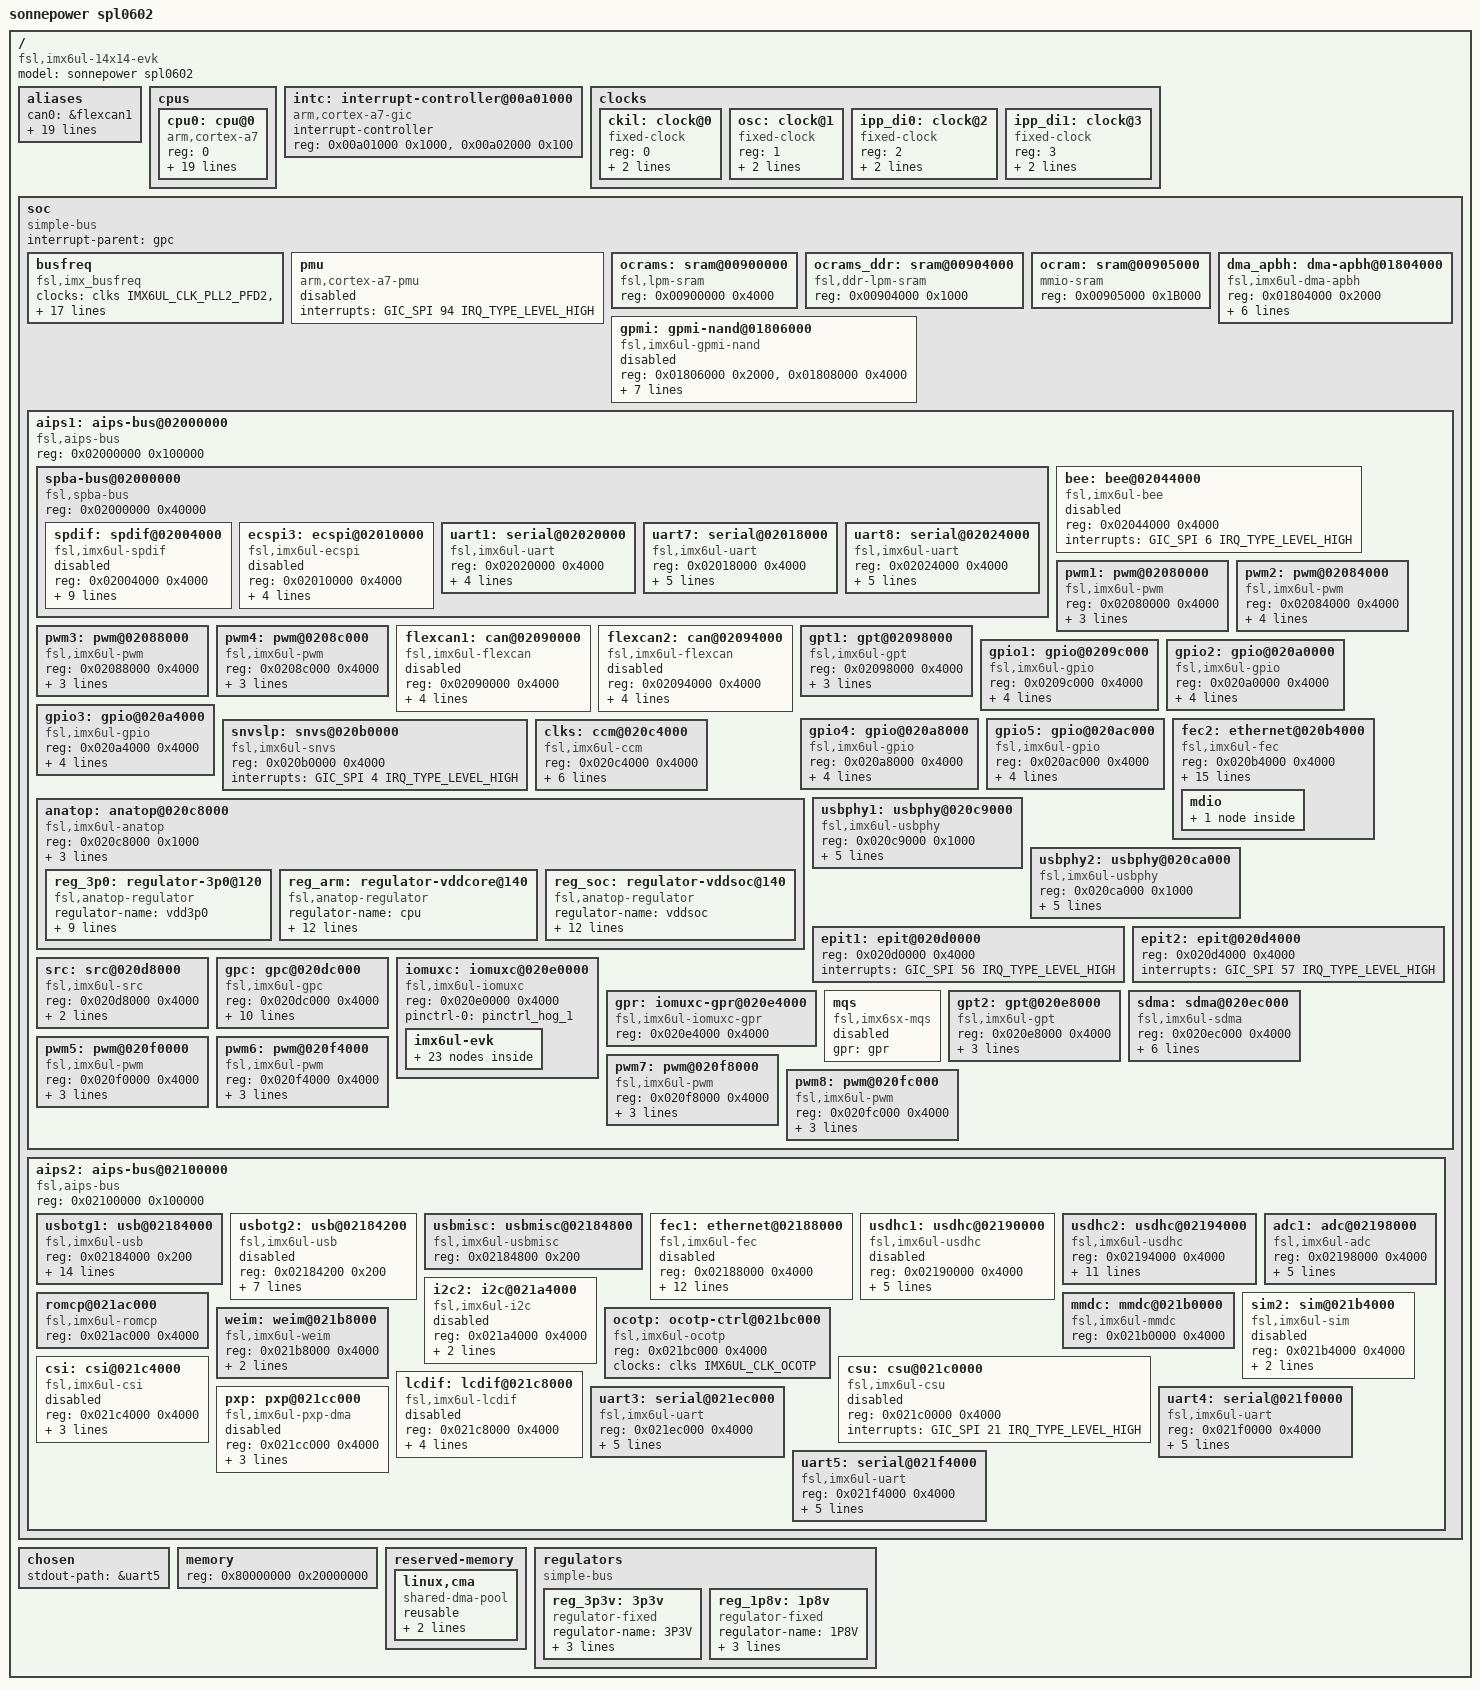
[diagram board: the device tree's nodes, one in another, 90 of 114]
/*
 * Copyright (C) 2016 Freescale Semiconductor, Inc.
 *
 * This program is free software; you can redistribute it and/or modify
 * it under the terms of the GNU General Public License version 2 as
 * published by the Free Software Foundation.
 */

/dts-v1/;

#include <dt-bindings/clock/imx6ul-clock.h>
#include <dt-bindings/gpio/gpio.h>
#include <dt-bindings/interrupt-controller/arm-gic.h>
#include "imx6ul-pinfunc.h"
#include "skeleton.dtsi"

/ {
	aliases {
		can0 = &flexcan1;
		can1 = &flexcan2;
		ethernet0 = &fec2;
		gpio0 = &gpio1;
		gpio1 = &gpio2;
		gpio2 = &gpio3;
		gpio3 = &gpio4;
		gpio4 = &gpio5;
		
		i2c1 = &i2c2;
		mmc0 = &usdhc1;
		mmc1 = &usdhc2;
             
		serial0 = &uart5;
		serial1 = &uart7;
		serial2 = &uart8;
  		serial4 = &uart4;

                //RS485
		serial5 = &uart3;

		//bluth
		serial6 = &uart1;
		//spi0 = &ecspi1;
		//spi1 = &ecspi2;
		spi2 = &ecspi3;
		//spi3 = &ecspi4;
		usbphy0 = &usbphy1;
		usbphy1 = &usbphy2;
	};

	cpus {
		#address-cells = <1>;
		#size-cells = <0>;

		cpu0: cpu@0 {
			compatible = "arm,cortex-a7";
			device_type = "cpu";
			reg = <0>;
			clock-latency = <61036>; /* two CLK32 periods */
			clock-frequency = <528000000>;
			operating-points = <
				/* kHz	uV */
				696000	1275000
				528000	1175000
				396000	1025000
				198000	950000
			>;
			fsl,soc-operating-points = <
				/* KHz	uV */
				696000	1275000
				528000	1175000
				396000	1175000
				198000	1175000
			>;
			clocks = <&clks IMX6UL_CLK_ARM>,
				 <&clks IMX6UL_CLK_PLL2_BUS>,
				 <&clks IMX6UL_CLK_PLL2_PFD2>,
				 <&clks IMX6UL_CA7_SECONDARY_SEL>,
				 <&clks IMX6UL_CLK_STEP>,
				 <&clks IMX6UL_CLK_PLL1_SW>,
				 <&clks IMX6UL_CLK_PLL1_SYS>,
				 <&clks IMX6UL_PLL1_BYPASS>,
				 <&clks IMX6UL_CLK_PLL1>,
				 <&clks IMX6UL_PLL1_BYPASS_SRC>,
				 <&clks IMX6UL_CLK_OSC>;
			clock-names = "arm", "pll2_bus",  "pll2_pfd2_396m", 
						"secondary_sel", "step", "pll1_sw", 
						"pll1_sys", "pll1_bypass", "pll1", 
						"pll1_bypass_src", "osc";
		};
	};

	intc: interrupt-controller@00a01000 {
		compatible = "arm,cortex-a7-gic";
		#interrupt-cells = <3>;
		interrupt-controller;
		reg = <0x00a01000 0x1000>,
		      <0x00a02000 0x100>;
	};

	clocks {
		#address-cells = <1>;
		#size-cells = <0>;

		ckil: clock@0 {
			compatible = "fixed-clock";
			reg = <0>;
			#clock-cells = <0>;
			clock-frequency = <32768>;
			clock-output-names = "ckil";
		};

		osc: clock@1 {
			compatible = "fixed-clock";
			reg = <1>;
			#clock-cells = <0>;
			clock-frequency = <24000000>;
			clock-output-names = "osc";
		};

		ipp_di0: clock@2 {
			compatible = "fixed-clock";
			reg = <2>;
			#clock-cells = <0>;
			clock-frequency = <0>;
			clock-output-names = "ipp_di0";
		};

		ipp_di1: clock@3 {
			compatible = "fixed-clock";
			reg = <3>;
			#clock-cells = <0>;
			clock-frequency = <0>;
			clock-output-names = "ipp_di1";
		};
	};

	soc {
		#address-cells = <1>;
		#size-cells = <1>;
		compatible = "simple-bus";
		interrupt-parent = <&gpc>;
		ranges;

		busfreq {
			compatible = "fsl,imx_busfreq";
			clocks = <&clks IMX6UL_CLK_PLL2_PFD2>, <&clks IMX6UL_CLK_PLL2_198M>,
				 <&clks IMX6UL_CLK_PLL2_BUS>, <&clks IMX6UL_CLK_ARM>,
				 <&clks IMX6UL_CLK_PLL3_USB_OTG>, <&clks IMX6UL_CLK_PERIPH>,
				 <&clks IMX6UL_CLK_PERIPH_PRE>, <&clks IMX6UL_CLK_PERIPH_CLK2>,
				 <&clks IMX6UL_CLK_PERIPH_CLK2_SEL>, <&clks IMX6UL_CLK_OSC>,
				 <&clks IMX6UL_CLK_AHB>, <&clks IMX6UL_CLK_AXI>,
				 <&clks IMX6UL_CLK_PERIPH2>, <&clks IMX6UL_CLK_PERIPH2_PRE>,
				 <&clks IMX6UL_CLK_PERIPH2_CLK2>, <&clks IMX6UL_CLK_PERIPH2_CLK2_SEL>,
				 <&clks IMX6UL_CLK_STEP>, <&clks IMX6UL_CLK_MMDC_P0_FAST>;
			clock-names = "pll2_pfd2_396m", "pll2_198m", "pll2_bus", "arm", "pll3_usb_otg",
				      "periph", "periph_pre", "periph_clk2", "periph_clk2_sel", "osc",
				      "ahb", "ocram", "periph2", "periph2_pre", "periph2_clk2", "periph2_clk2_sel",
				      "step", "mmdc";
			fsl,max_ddr_freq = <400000000>;
		};

		pmu {
			compatible = "arm,cortex-a7-pmu";
			interrupts = <GIC_SPI 94 IRQ_TYPE_LEVEL_HIGH>;
			status = "disabled";
		};

		ocrams: sram@00900000 {
			compatible = "fsl,lpm-sram";
			reg = <0x00900000 0x4000>;
		};

		ocrams_ddr: sram@00904000 {
			compatible = "fsl,ddr-lpm-sram";
			reg = <0x00904000 0x1000>;
		};

		ocram: sram@00905000 {
			compatible = "mmio-sram";
			reg = <0x00905000 0x1B000>;
		};

		dma_apbh: dma-apbh@01804000 {
			compatible = "fsl,imx6ul-dma-apbh", "fsl,imx28-dma-apbh";
			reg = <0x01804000 0x2000>;
			interrupts = <GIC_SPI 13 IRQ_TYPE_LEVEL_HIGH>,
					<GIC_SPI 13 IRQ_TYPE_LEVEL_HIGH>,
					<GIC_SPI 13 IRQ_TYPE_LEVEL_HIGH>,
					<GIC_SPI 13 IRQ_TYPE_LEVEL_HIGH>;
			interrupt-names = "gpmi0", "gpmi1", "gpmi2", "gpmi3";
			#dma-cells = <1>;
			dma-channels = <4>;
			clocks = <&clks IMX6UL_CLK_APBHDMA>;
		};

		gpmi: gpmi-nand@01806000{
			compatible = "fsl,imx6ul-gpmi-nand";
			#address-cells = <1>;
			#size-cells = <1>;
			reg = <0x01806000 0x2000>, <0x01808000 0x4000>;
			reg-names = "gpmi-nand", "bch";
			interrupts = <GIC_SPI 15 IRQ_TYPE_LEVEL_HIGH>;
			interrupt-names = "bch";
			clocks = <&clks IMX6UL_CLK_GPMI_IO>,
				<&clks IMX6UL_CLK_GPMI_APB>,
				<&clks IMX6UL_CLK_GPMI_BCH>,
				<&clks IMX6UL_CLK_GPMI_BCH_APB>,
				<&clks IMX6UL_CLK_PER_BCH>;
			clock-names = "gpmi_io", "gpmi_apb", "gpmi_bch",
				"gpmi_bch_apb", "per1_bch";
			dmas = <&dma_apbh 0>;
			dma-names = "rx-tx";
			status = "disabled";
		};

		aips1: aips-bus@02000000 {
			compatible = "fsl,aips-bus", "simple-bus";
			#address-cells = <1>;
			#size-cells = <1>;
			reg = <0x02000000 0x100000>;
			ranges;

			spba-bus@02000000 {
				compatible = "fsl,spba-bus", "simple-bus";
				#address-cells = <1>;
				#size-cells = <1>;
				reg = <0x02000000 0x40000>;
				ranges;

				spdif: spdif@02004000 {
					compatible = "fsl,imx6ul-spdif", "fsl,imx35-spdif";
					reg = <0x02004000 0x4000>;
					interrupts = <GIC_SPI 52 IRQ_TYPE_LEVEL_HIGH>;
					dmas = <&sdma 41 18 0>,
					       <&sdma 42 18 0>;
					dma-names = "rx", "tx";
					clocks = <&clks IMX6UL_CLK_SPDIF_GCLK>,
						 <&clks IMX6UL_CLK_OSC>,
						 <&clks IMX6UL_CLK_SPDIF>,
						 <&clks IMX6UL_CLK_DUMMY>, <&clks IMX6UL_CLK_DUMMY>, <&clks IMX6UL_CLK_DUMMY>,
						 <&clks IMX6UL_CLK_IPG>,
						 <&clks IMX6UL_CLK_DUMMY>, <&clks IMX6UL_CLK_DUMMY>,
						 <&clks IMX6UL_CLK_SPBA>;
					clock-names = "core", "rxtx0",
						      "rxtx1", "rxtx2",
						      "rxtx3", "rxtx4",
						      "rxtx5", "rxtx6",
						      "rxtx7", "dma";
					status = "disabled";
				};

				ecspi3: ecspi@02010000 {
					#address-cells = <1>;
					#size-cells = <0>;
					compatible = "fsl,imx6ul-ecspi", "fsl,imx51-ecspi";
					reg = <0x02010000 0x4000>;
					interrupts = <GIC_SPI 33 IRQ_TYPE_LEVEL_HIGH>;
					clocks = <&clks IMX6UL_CLK_ECSPI3>,
						 <&clks IMX6UL_CLK_ECSPI3>;
					clock-names = "ipg", "per";
					dmas = <&sdma 7 7 1>, <&sdma 8 7 2>;
					dma-names = "rx", "tx";
					status = "disabled";
				};
		        uart1: serial@02020000 {
					compatible = "fsl,imx6ul-uart",
						     "fsl,imx6q-uart", "fsl,imx21-uart";
					reg = <0x02020000 0x4000>;
					interrupts = <GIC_SPI 26 IRQ_TYPE_LEVEL_HIGH>;
					clocks = <&clks IMX6UL_CLK_UART1_IPG>,
						 <&clks IMX6UL_CLK_UART1_SERIAL>;
					clock-names = "ipg", "per";
					status = "disabled";
				};
			
				uart7: serial@02018000 {
					compatible = "fsl,imx6ul-uart",
						     "fsl,imx6q-uart", "fsl,imx21-uart";
					reg = <0x02018000 0x4000>;
					interrupts = <GIC_SPI 39 IRQ_TYPE_LEVEL_HIGH>;
					clocks = <&clks IMX6UL_CLK_UART7_IPG>,
						 <&clks IMX6UL_CLK_UART7_SERIAL>;
					clock-names = "ipg", "per";
					dmas = <&sdma 43 4 0>, <&sdma 44 4 0>;
					dma-names = "rx", "tx";
					status = "disabled";
				};

				uart8: serial@02024000 {
					compatible = "fsl,imx6ul-uart",
						     "fsl,imx6q-uart", "fsl,imx21-uart";
					reg = <0x02024000 0x4000>;
					interrupts = <GIC_SPI 40 IRQ_TYPE_LEVEL_HIGH>;
					clocks = <&clks IMX6UL_CLK_UART8_IPG>,
						 <&clks IMX6UL_CLK_UART8_SERIAL>;
					clock-names = "ipg", "per";
					dmas = <&sdma 45 4 0>, <&sdma 46 4 0>;
					dma-names = "rx", "tx";
					status = "disabled";
				};

			};


			bee: bee@02044000 {
				compatible = "fsl,imx6ul-bee";
				reg = <0x02044000 0x4000>;
				interrupts = <GIC_SPI 6 IRQ_TYPE_LEVEL_HIGH>;
				status = "disabled";
			};

			pwm1: pwm@02080000 {
				compatible = "fsl,imx6ul-pwm", "fsl,imx27-pwm";
				reg = <0x02080000 0x4000>;
				interrupts = <GIC_SPI 83 IRQ_TYPE_LEVEL_HIGH>;
				clocks = <&clks IMX6UL_CLK_PWM1>,
					 <&clks IMX6UL_CLK_PWM1>;
				clock-names = "ipg", "per";
				#pwm-cells = <2>;
			};

			pwm2: pwm@02084000 {
				compatible = "fsl,imx6ul-pwm", "fsl,imx27-pwm";
				reg = <0x02084000 0x4000>;
				interrupts = <GIC_SPI 84 IRQ_TYPE_LEVEL_HIGH>;
				clocks = <&clks IMX6UL_CLK_PWM2>,
					 <&clks IMX6UL_CLK_PWM2>;
				clock-names = "ipg", "per";
				#pwm-cells = <2>;
			};

			pwm3: pwm@02088000 {
				compatible = "fsl,imx6ul-pwm", "fsl,imx27-pwm";
				reg = <0x02088000 0x4000>;
				interrupts = <GIC_SPI 85 IRQ_TYPE_LEVEL_HIGH>;
				clocks = <&clks IMX6UL_CLK_PWM3>,
					 <&clks IMX6UL_CLK_PWM3>;
				clock-names = "ipg", "per";
				#pwm-cells = <2>;
			};

			pwm4: pwm@0208c000 {
				compatible = "fsl,imx6ul-pwm", "fsl,imx27-pwm";
				reg = <0x0208c000 0x4000>;
				interrupts = <GIC_SPI 86 IRQ_TYPE_LEVEL_HIGH>;
				clocks = <&clks IMX6UL_CLK_PWM4>,
					 <&clks IMX6UL_CLK_PWM4>;
				clock-names = "ipg", "per";
				#pwm-cells = <2>;
			};

			flexcan1: can@02090000 {
				compatible = "fsl,imx6ul-flexcan", "fsl,imx6q-flexcan";
				reg = <0x02090000 0x4000>;
				interrupts = <GIC_SPI 110 IRQ_TYPE_LEVEL_HIGH>;
				clocks = <&clks IMX6UL_CLK_CAN1_IPG>,
					 <&clks IMX6UL_CLK_CAN1_SERIAL>;
				clock-names = "ipg", "per";
				stop-mode = <&gpr 0x10 1 0x10 17>;
				status = "disabled";
			};

			flexcan2: can@02094000 {
				compatible = "fsl,imx6ul-flexcan", "fsl,imx6q-flexcan";
				reg = <0x02094000 0x4000>;
				interrupts = <GIC_SPI 111 IRQ_TYPE_LEVEL_HIGH>;
				clocks = <&clks IMX6UL_CLK_CAN2_IPG>,
					 <&clks IMX6UL_CLK_CAN2_SERIAL>;
				clock-names = "ipg", "per";
				stop-mode = <&gpr 0x10 2 0x10 18>;
				status = "disabled";
			};

			gpt1: gpt@02098000 {
				compatible = "fsl,imx6ul-gpt", "fsl,imx31-gpt";
				reg = <0x02098000 0x4000>;
				interrupts = <GIC_SPI 55 IRQ_TYPE_LEVEL_HIGH>;
				clocks = <&clks IMX6UL_CLK_GPT1_BUS>,
					 <&clks IMX6UL_CLK_GPT1_SERIAL>;
				clock-names = "ipg", "per";
			};

			gpio1: gpio@0209c000 {
				compatible = "fsl,imx6ul-gpio", "fsl,imx35-gpio";
				reg = <0x0209c000 0x4000>;
				interrupts = <GIC_SPI 66 IRQ_TYPE_LEVEL_HIGH>,
					     <GIC_SPI 67 IRQ_TYPE_LEVEL_HIGH>;
				gpio-controller;
				#gpio-cells = <2>;
				interrupt-controller;
				#interrupt-cells = <2>;
			};

			gpio2: gpio@020a0000 {
				compatible = "fsl,imx6ul-gpio", "fsl,imx35-gpio";
				reg = <0x020a0000 0x4000>;
				interrupts = <GIC_SPI 68 IRQ_TYPE_LEVEL_HIGH>,
					     <GIC_SPI 69 IRQ_TYPE_LEVEL_HIGH>;
				gpio-controller;
				#gpio-cells = <2>;
				interrupt-controller;
				#interrupt-cells = <2>;
			};

			gpio3: gpio@020a4000 {
				compatible = "fsl,imx6ul-gpio", "fsl,imx35-gpio";
				reg = <0x020a4000 0x4000>;
				interrupts = <GIC_SPI 70 IRQ_TYPE_LEVEL_HIGH>,
					     <GIC_SPI 71 IRQ_TYPE_LEVEL_HIGH>;
				gpio-controller;
				#gpio-cells = <2>;
				interrupt-controller;
				#interrupt-cells = <2>;
			};

			gpio4: gpio@020a8000 {
				compatible = "fsl,imx6ul-gpio", "fsl,imx35-gpio";
				reg = <0x020a8000 0x4000>;
				interrupts = <GIC_SPI 72 IRQ_TYPE_LEVEL_HIGH>,
					     <GIC_SPI 73 IRQ_TYPE_LEVEL_HIGH>;
				gpio-controller;
				#gpio-cells = <2>;
				interrupt-controller;
				#interrupt-cells = <2>;
			};

			gpio5: gpio@020ac000 {
				compatible = "fsl,imx6ul-gpio", "fsl,imx35-gpio";
				reg = <0x020ac000 0x4000>;
				interrupts = <GIC_SPI 74 IRQ_TYPE_LEVEL_HIGH>,
					     <GIC_SPI 75 IRQ_TYPE_LEVEL_HIGH>;
				gpio-controller;
				#gpio-cells = <2>;
				interrupt-controller;
				#interrupt-cells = <2>;
			};

			snvslp: snvs@020b0000 {
				compatible = "fsl,imx6ul-snvs";
				reg = <0x020b0000 0x4000>;
				interrupts = <GIC_SPI 4 IRQ_TYPE_LEVEL_HIGH>;
			};

			fec2: ethernet@020b4000 {
				compatible = "fsl,imx6ul-fec", "fsl,imx6q-fec";
				reg = <0x020b4000 0x4000>;
				interrupts = <GIC_SPI 120 IRQ_TYPE_LEVEL_HIGH>,
					     <GIC_SPI 121 IRQ_TYPE_LEVEL_HIGH>;
				clocks = <&clks IMX6UL_CLK_ENET>,
					 <&clks IMX6UL_CLK_ENET_AHB>,
					 <&clks IMX6UL_CLK_ENET_PTP>,
					 <&clks IMX6UL_CLK_ENET2_REF_125M>,
					 <&clks IMX6UL_CLK_ENET2_REF_125M>;
				clock-names = "ipg", "ahb", "ptp",
					      "enet_clk_ref", "enet_out";
				stop-mode = <&gpr 0x10 4>;
				fsl,num-tx-queues=<1>;
				fsl,num-rx-queues=<1>;
				fsl,magic-packet;
				fsl,wakeup_irq = <0>;
				status = "disabled";
			};

			clks: ccm@020c4000 {
				compatible = "fsl,imx6ul-ccm";
				reg = <0x020c4000 0x4000>;
				interrupts = <GIC_SPI 87 IRQ_TYPE_LEVEL_HIGH>,
					     <GIC_SPI 88 IRQ_TYPE_LEVEL_HIGH>;
				#clock-cells = <1>;
				clocks = <&ckil>, <&osc>, <&ipp_di0>, <&ipp_di1>;
				clock-names = "ckil", "osc", "ipp_di0", "ipp_di1";
			};

			anatop: anatop@020c8000 {
				compatible = "fsl,imx6ul-anatop", "fsl,imx6q-anatop",
					     "syscon", "simple-bus";
				reg = <0x020c8000 0x1000>;
				interrupts = <GIC_SPI 49 IRQ_TYPE_LEVEL_HIGH>,
					     <GIC_SPI 54 IRQ_TYPE_LEVEL_HIGH>,
					     <GIC_SPI 127 IRQ_TYPE_LEVEL_HIGH>;

				reg_3p0: regulator-3p0@120 {
					compatible = "fsl,anatop-regulator";
					regulator-name = "vdd3p0";
					regulator-min-microvolt = <2625000>;
					regulator-max-microvolt = <3400000>;
					anatop-reg-offset = <0x120>;
					anatop-vol-bit-shift = <8>;
					anatop-vol-bit-width = <5>;
					anatop-min-bit-val = <0>;
					anatop-min-voltage = <2625000>;
					anatop-max-voltage = <3400000>;
					anatop-enable-bit = <0>;
				};

				reg_arm: regulator-vddcore@140 {
					compatible = "fsl,anatop-regulator";
					regulator-name = "cpu";
					regulator-min-microvolt = <725000>;
					regulator-max-microvolt = <1450000>;
					regulator-always-on;
					anatop-reg-offset = <0x140>;
					anatop-vol-bit-shift = <0>;
					anatop-vol-bit-width = <5>;
					anatop-delay-reg-offset = <0x170>;
					anatop-delay-bit-shift = <24>;
					anatop-delay-bit-width = <2>;
					anatop-min-bit-val = <1>;
					anatop-min-voltage = <725000>;
					anatop-max-voltage = <1450000>;
				};

				reg_soc: regulator-vddsoc@140 {
					compatible = "fsl,anatop-regulator";
					regulator-name = "vddsoc";
					regulator-min-microvolt = <725000>;
					regulator-max-microvolt = <1450000>;
					regulator-always-on;
					anatop-reg-offset = <0x140>;
					anatop-vol-bit-shift = <18>;
					anatop-vol-bit-width = <5>;
					anatop-delay-reg-offset = <0x170>;
					anatop-delay-bit-shift = <28>;
					anatop-delay-bit-width = <2>;
					anatop-min-bit-val = <1>;
					anatop-min-voltage = <725000>;
					anatop-max-voltage = <1450000>;
				};
			};

			usbphy1: usbphy@020c9000 {
				compatible = "fsl,imx6ul-usbphy", "fsl,imx23-usbphy";
				reg = <0x020c9000 0x1000>;
				interrupts = <GIC_SPI 44 IRQ_TYPE_LEVEL_HIGH>;
				clocks = <&clks IMX6UL_CLK_USBPHY1>;
				phy-3p0-supply = <&reg_3p0>;
				fsl,anatop = <&anatop>;
			};

			usbphy2: usbphy@020ca000 {
				compatible = "fsl,imx6ul-usbphy", "fsl,imx23-usbphy";
				reg = <0x020ca000 0x1000>;
				interrupts = <GIC_SPI 45 IRQ_TYPE_LEVEL_HIGH>;
				clocks = <&clks IMX6UL_CLK_USBPHY2>;
				phy-3p0-supply = <&reg_3p0>;
				fsl,anatop = <&anatop>;
			};

			epit1: epit@020d0000 {
				reg = <0x020d0000 0x4000>;
				interrupts = <GIC_SPI 56 IRQ_TYPE_LEVEL_HIGH>;
			};

			epit2: epit@020d4000 {
				reg = <0x020d4000 0x4000>;
				interrupts = <GIC_SPI 57 IRQ_TYPE_LEVEL_HIGH>;
			};

			src: src@020d8000 {
				compatible = "fsl,imx6ul-src", "fsl,imx51-src";
				reg = <0x020d8000 0x4000>;
				interrupts = <GIC_SPI 91 IRQ_TYPE_LEVEL_HIGH>,
					     <GIC_SPI 96 IRQ_TYPE_LEVEL_HIGH>;
				#reset-cells = <1>;
			};

			gpc: gpc@020dc000 {
				compatible = "fsl,imx6ul-gpc", "fsl,imx6q-gpc";
				reg = <0x020dc000 0x4000>;
				interrupt-controller;
				#interrupt-cells = <3>;
				interrupts = <GIC_SPI 89 IRQ_TYPE_LEVEL_HIGH>;
				interrupt-parent = <&intc>;
				fsl,mf-mix-wakeup-irq = <0x7c00000 0x7d00 0x0 0x1400640>;
			};

			iomuxc: iomuxc@020e0000 {
				compatible = "fsl,imx6ul-iomuxc";
				reg = <0x020e0000 0x4000>;
			};

			gpr: iomuxc-gpr@020e4000 {
				compatible = "fsl,imx6ul-iomuxc-gpr", "syscon";
				reg = <0x020e4000 0x4000>;
			};

			mqs: mqs {
                compatible = "fsl,imx6sx-mqs";
                gpr = <&gpr>;
                status = "disabled";
            };

			gpt2: gpt@020e8000 {
				compatible = "fsl,imx6ul-gpt", "fsl,imx31-gpt";
				reg = <0x020e8000 0x4000>;
				interrupts = <GIC_SPI 109 IRQ_TYPE_LEVEL_HIGH>;
				clocks = <&clks IMX6UL_CLK_DUMMY>,
					 <&clks IMX6UL_CLK_DUMMY>;
				clock-names = "ipg", "per";
			};

			sdma: sdma@020ec000 {
				compatible = "fsl,imx6ul-sdma", "fsl,imx35-sdma";
				reg = <0x020ec000 0x4000>;
				interrupts = <GIC_SPI 2 IRQ_TYPE_LEVEL_HIGH>;
				clocks = <&clks IMX6UL_CLK_SDMA>,
					 <&clks IMX6UL_CLK_SDMA>;
				clock-names = "ipg", "ahb";
				#dma-cells = <3>;
				iram = <&ocram>;
				fsl,sdma-ram-script-name = "imx/sdma/sdma-imx6q.bin";
			};

			pwm5: pwm@020f0000 {
				compatible = "fsl,imx6ul-pwm", "fsl,imx27-pwm";
				reg = <0x020f0000 0x4000>;
				interrupts = <GIC_SPI 114 IRQ_TYPE_LEVEL_HIGH>;
				clocks = <&clks IMX6UL_CLK_PWM5>,
					 <&clks IMX6UL_CLK_PWM5>;
				clock-names = "ipg", "per";
				#pwm-cells = <2>;
			};

			pwm6: pwm@020f4000 {
				compatible = "fsl,imx6ul-pwm", "fsl,imx27-pwm";
				reg = <0x020f4000 0x4000>;
				interrupts = <GIC_SPI 115 IRQ_TYPE_LEVEL_HIGH>;
				clocks = <&clks IMX6UL_CLK_PWM6>,
					 <&clks IMX6UL_CLK_PWM6>;
				clock-names = "ipg", "per";
				#pwm-cells = <2>;
			};

			pwm7: pwm@020f8000 {
				compatible = "fsl,imx6ul-pwm", "fsl,imx27-pwm";
				reg = <0x020f8000 0x4000>;
				interrupts = <GIC_SPI 116 IRQ_TYPE_LEVEL_HIGH>;
				clocks = <&clks IMX6UL_CLK_PWM7>,
					 <&clks IMX6UL_CLK_PWM7>;
				clock-names = "ipg", "per";
				#pwm-cells = <2>;
			};

			pwm8: pwm@020fc000 {
				compatible = "fsl,imx6ul-pwm", "fsl,imx27-pwm";
				reg = <0x020fc000 0x4000>;
				interrupts = <GIC_SPI 117 IRQ_TYPE_LEVEL_HIGH>;
				clocks = <&clks IMX6UL_CLK_PWM8>,
					 <&clks IMX6UL_CLK_PWM8>;
				clock-names = "ipg", "per";
				#pwm-cells = <2>;
			};
		};

		aips2: aips-bus@02100000 {
			compatible = "fsl,aips-bus", "simple-bus";
			#address-cells = <1>;
			#size-cells = <1>;
			reg = <0x02100000 0x100000>;
			ranges;

			/*crypto: caam@2140000 {
				compatible = "fsl,imx6ul-caam", "fsl,sec-v4.0";
				#address-cells = <1>;
				#size-cells = <1>;
				reg = <0x2140000 0x3c000>;
				ranges = <0 0x2140000 0x3c000>;
				interrupts = <GIC_SPI 48 IRQ_TYPE_LEVEL_HIGH>;
				clocks = <&clks IMX6UL_CLK_CAAM_IPG>, <&clks IMX6UL_CLK_CAAM_ACLK>,
				       	 <&clks IMX6UL_CLK_CAAM_MEM>;
				clock-names = "caam_ipg", "caam_aclk", "caam_mem";

				sec_jr0: jr0@1000 {
					compatible = "fsl,sec-v4.0-job-ring";
					reg = <0x1000 0x1000>;
					interrupts = <GIC_SPI 105 IRQ_TYPE_LEVEL_HIGH>;
				};

				sec_jr1: jr1@2000 {
					compatible = "fsl,sec-v4.0-job-ring";
					reg = <0x2000 0x1000>;
					interrupts = <GIC_SPI 106 IRQ_TYPE_LEVEL_HIGH>;
				};
				sec_jr2: jr2@3000 {
					compatible = "fsl,sec-v4.0-job-ring";
					reg = <0x3000 0x1000>;
					interrupts = <GIC_SPI 46 IRQ_TYPE_LEVEL_HIGH>;
				};
			};*/

			usbotg1: usb@02184000 {
				compatible = "fsl,imx6ul-usb", "fsl,imx27-usb";
				reg = <0x02184000 0x200>;
				interrupts = <GIC_SPI 43 IRQ_TYPE_LEVEL_HIGH>;
				clocks = <&clks IMX6UL_CLK_USBOH3>;
				fsl,usbphy = <&usbphy1>;
				fsl,usbmisc = <&usbmisc 0>;
				fsl,anatop = <&anatop>;
				ahb-burst-config = <0x0>;
				tx-burst-size-dword = <0x10>;
				rx-burst-size-dword = <0x10>;
				status = "disabled";
			};

			usbotg2: usb@02184200 {
				compatible = "fsl,imx6ul-usb", "fsl,imx27-usb";
				reg = <0x02184200 0x200>;
				interrupts = <GIC_SPI 42 IRQ_TYPE_LEVEL_HIGH>;
				clocks = <&clks IMX6UL_CLK_USBOH3>;
				fsl,usbphy = <&usbphy2>;
				fsl,usbmisc = <&usbmisc 1>;
                ahb-burst-config = <0x0>;
                tx-burst-size-dword = <0x10>;
                rx-burst-size-dword = <0x10>;
				status = "disabled";
			};

			usbmisc: usbmisc@02184800 {
				#index-cells = <1>;
				compatible = "fsl,imx6ul-usbmisc", "fsl,imx6q-usbmisc";
				reg = <0x02184800 0x200>;
			};

			fec1: ethernet@02188000 {
				compatible = "fsl,imx6ul-fec", "fsl,imx6q-fec";
				reg = <0x02188000 0x4000>;
				interrupts = <GIC_SPI 118 IRQ_TYPE_LEVEL_HIGH>,
					     <GIC_SPI 119 IRQ_TYPE_LEVEL_HIGH>;
				clocks = <&clks IMX6UL_CLK_ENET>,
					 <&clks IMX6UL_CLK_ENET_AHB>,
					 <&clks IMX6UL_CLK_ENET_PTP>,
					 <&clks IMX6UL_CLK_ENET_REF>,
					 <&clks IMX6UL_CLK_ENET_REF>;
				clock-names = "ipg", "ahb", "ptp",
					      "enet_clk_ref", "enet_out";
				stop-mode = <&gpr 0x10 3>;
				fsl,num-tx-queues=<1>;
				fsl,num-rx-queues=<1>;
				fsl,magic-packet;
				fsl,wakeup_irq = <0>;
				status = "disabled";
                        };

			/*sim1: sim@0218c000 {
				compatible = "fsl,imx6ul-sim";
				reg = <0x0218c000 0x4000>;
				interrupts = <GIC_SPI 112 IRQ_TYPE_LEVEL_HIGH>;
				status = "disabled";
			};*/

			usdhc1: usdhc@02190000 {
				compatible = "fsl,imx6ul-usdhc", "fsl,imx6sx-usdhc";
				reg = <0x02190000 0x4000>;
				interrupts = <GIC_SPI 22 IRQ_TYPE_LEVEL_HIGH>;
				clocks = <&clks IMX6UL_CLK_USDHC1>,
					 <&clks IMX6UL_CLK_USDHC1>,
					 <&clks IMX6UL_CLK_USDHC1>;
				clock-names = "ipg", "ahb", "per";
				bus-width = <8>;
				status = "disabled";
			};

			usdhc2: usdhc@02194000 {
				compatible = "fsl,imx6ul-usdhc", "fsl,imx6sx-usdhc";
				reg = <0x02194000 0x4000>;
				interrupts = <GIC_SPI 23 IRQ_TYPE_LEVEL_HIGH>;
				clocks = <&clks IMX6UL_CLK_USDHC2>,
					 <&clks IMX6UL_CLK_USDHC2>,
					 <&clks IMX6UL_CLK_USDHC2>;
				clock-names = "ipg", "ahb", "per";
				bus-width = <8>;
				status = "disabled";
			};

			adc1: adc@02198000 {
				compatible = "fsl,imx6ul-adc", "fsl,vf610-adc";
				reg = <0x02198000 0x4000>;
				interrupts = <GIC_SPI 100 IRQ_TYPE_LEVEL_HIGH>;
				clocks = <&clks IMX6UL_CLK_ADC1>;
				num-channels = <2>;
				clock-names = "adc";
				status = "disabled";
                        };
/*
			i2c1: i2c@021a0000 {
				#address-cells = <1>;
				#size-cells = <0>;
				compatible = "fsl,imx6ul-i2c", "fsl,imx21-i2c";
				reg = <0x021a0000 0x4000>;
				interrupts = <GIC_SPI 36 IRQ_TYPE_LEVEL_HIGH>;
				clocks = <&clks IMX6UL_CLK_I2C1>;
				status = "disabled";
			};*/

			i2c2: i2c@021a4000 {
				#address-cells = <1>;
				#size-cells = <0>;
				compatible = "fsl,imx6ul-i2c", "fsl,imx21-i2c";
				reg = <0x021a4000 0x4000>;
				interrupts = <GIC_SPI 37 IRQ_TYPE_LEVEL_HIGH>;
				clocks = <&clks IMX6UL_CLK_I2C2>;
				status = "disabled";
			};

			/*i2c3: i2c@021a8000 {
				#address-cells = <1>;
				#size-cells = <0>;
				compatible = "fsl,imx6ul-i2c", "fsl,imx21-i2c";
				reg = <0x021a8000 0x4000>;
				interrupts = <GIC_SPI 38 IRQ_TYPE_LEVEL_HIGH>;
				clocks = <&clks IMX6UL_CLK_I2C3>;
				status = "disabled";
			};*/

			romcp@021ac000 {
				compatible = "fsl,imx6ul-romcp", "syscon";
				reg = <0x021ac000 0x4000>;
			};

			mmdc: mmdc@021b0000 {
				compatible = "fsl,imx6ul-mmdc", "fsl,imx6q-mmdc";
				reg = <0x021b0000 0x4000>;
			};

			sim2: sim@021b4000 {
				compatible = "fsl,imx6ul-sim";
				reg = <0x021b4000 0x4000>;
				interrupts = <GIC_SPI 113 IRQ_TYPE_LEVEL_HIGH>;
				clocks = <&clks IMX6UL_CLK_SIM2>;
				clock-names = "sim";
				status = "disabled";
			};

			weim: weim@021b8000 {
				compatible = "fsl,imx6ul-weim", "fsl,imx6q-weim";
				reg = <0x021b8000 0x4000>;
				interrupts = <GIC_SPI 14 IRQ_TYPE_LEVEL_HIGH>;
				clocks = <&clks IMX6UL_CLK_DUMMY>;
			};

			ocotp: ocotp-ctrl@021bc000 {
                compatible = "fsl,imx6ul-ocotp", "syscon";
				reg = <0x021bc000 0x4000>;
				clocks = <&clks IMX6UL_CLK_OCOTP>;
			};

			csu: csu@021c0000 {
				compatible = "fsl,imx6ul-csu";
				reg = <0x021c0000 0x4000>;
				interrupts = <GIC_SPI 21 IRQ_TYPE_LEVEL_HIGH>;
				status = "disabled";
			};

			csi: csi@021c4000 {
				compatible = "fsl,imx6ul-csi", "fsl,imx6s-csi";
				reg = <0x021c4000 0x4000>;
				interrupts = <GIC_SPI 7 IRQ_TYPE_LEVEL_HIGH>;
				clocks = <&clks IMX6UL_CLK_DUMMY>,
					<&clks IMX6UL_CLK_CSI>,
					<&clks IMX6UL_CLK_DUMMY>;
				clock-names = "disp-axi", "csi_mclk", "disp_dcic";
				status = "disabled";
			};

			lcdif: lcdif@021c8000 {
				compatible = "fsl,imx6ul-lcdif", "fsl,imx28-lcdif";
				reg = <0x021c8000 0x4000>;
				interrupts = <GIC_SPI 5 IRQ_TYPE_LEVEL_HIGH>;
				clocks = <&clks IMX6UL_CLK_LCDIF_PIX>,
					 <&clks IMX6UL_CLK_LCDIF_APB>,
					 <&clks IMX6UL_CLK_DUMMY>;
				clock-names = "pix", "axi", "disp_axi";
				status = "disabled";
			};

			pxp: pxp@021cc000 {
				compatible = "fsl,imx6ul-pxp-dma", "fsl,imx6sl-pxp-dma", "fsl,imx6dl-pxp-dma";
				reg = <0x021cc000 0x4000>;
				interrupts = <GIC_SPI 8 IRQ_TYPE_LEVEL_HIGH>;
				clocks = <&clks IMX6UL_CLK_PXP>,
					 <&clks IMX6UL_CLK_DUMMY>;
				clock-names = "pxp-axi", "disp-axi";
				status = "disabled";
			};
/*
			qspi: qspi@021e0000 {
				#address-cells = <1>;
				#size-cells = <0>;
				compatible = "fsl,imx6ul-qspi";
				reg = <0x021e0000 0x4000>, <0x60000000 0x10000000>;
				reg-names = "QuadSPI", "QuadSPI-memory";
				interrupts = <GIC_SPI 107 IRQ_TYPE_LEVEL_HIGH>;
				clocks = <&clks IMX6UL_CLK_QSPI>,
					 <&clks IMX6UL_CLK_QSPI>;
				clock-names = "qspi_en", "qspi";
				status = "disabled";
			};
			uart2: serial@021e8000 {
				compatible = "fsl,imx6ul-uart",
					     "fsl,imx6q-uart", "fsl,imx21-uart";
				reg = <0x021e8000 0x4000>;
				interrupts = <GIC_SPI 27 IRQ_TYPE_LEVEL_HIGH>;
				clocks = <&clks IMX6UL_CLK_UART2_IPG>,
					 <&clks IMX6UL_CLK_UART2_SERIAL>;
				clock-names = "ipg", "per";
				dmas = <&sdma 27 4 0>, <&sdma 28 4 0>;
				dma-names = "rx", "tx";
				status = "disabled";
			};
*/
			uart3: serial@021ec000 {
				compatible = "fsl,imx6ul-uart",
					     "fsl,imx6q-uart", "fsl,imx21-uart";
				reg = <0x021ec000 0x4000>;
				interrupts = <GIC_SPI 28 IRQ_TYPE_LEVEL_HIGH>;
				clocks = <&clks IMX6UL_CLK_UART3_IPG>,
					 <&clks IMX6UL_CLK_UART3_SERIAL>;
				clock-names = "ipg", "per";
				dmas = <&sdma 29 4 0>, <&sdma 30 4 0>;
				dma-names = "rx", "tx";
				status = "disabled";
			};


			uart4: serial@021f0000 {
				compatible = "fsl,imx6ul-uart",
					     "fsl,imx6q-uart", "fsl,imx21-uart";
				reg = <0x021f0000 0x4000>;
				interrupts = <GIC_SPI 29 IRQ_TYPE_LEVEL_HIGH>;
				clocks = <&clks IMX6UL_CLK_UART4_IPG>,
					 <&clks IMX6UL_CLK_UART4_SERIAL>;
				clock-names = "ipg", "per";
				dmas = <&sdma 31 4 0>, <&sdma 32 4 0>;
				dma-names = "rx", "tx";
				status = "disabled";
			};

			uart5: serial@021f4000 {
				compatible = "fsl,imx6ul-uart",
					     "fsl,imx6q-uart", "fsl,imx21-uart";
				reg = <0x021f4000 0x4000>;
				interrupts = <GIC_SPI 30 IRQ_TYPE_LEVEL_HIGH>;
				clocks = <&clks IMX6UL_CLK_UART5_IPG>,
					 <&clks IMX6UL_CLK_UART5_SERIAL>;
				clock-names = "ipg", "per";
				dmas = <&sdma 33 4 0>, <&sdma 34 4 0>;
				dma-names = "rx", "tx";
				status = "disabled";
			};

			/*i2c4: i2c@021f8000 {
				#address-cells = <1>;
				#size-cells = <0>;
				compatible = "fsl,imx6ul-i2c", "fsl,imx21-i2c";
				reg = <0x021f8000 0x4000>;
				interrupts = <GIC_SPI 35 IRQ_TYPE_LEVEL_HIGH>;
				clocks = <&clks IMX6UL_CLK_I2C4>;
				status = "disabled";
			};

			uart6: serial@021fc000 {
				compatible = "fsl,imx6ul-uart",
					     "fsl,imx6q-uart", "fsl,imx21-uart";
				reg = <0x021fc000 0x4000>;
				interrupts = <GIC_SPI 17 IRQ_TYPE_LEVEL_HIGH>;
				clocks = <&clks IMX6UL_CLK_UART6_IPG>,
					 <&clks IMX6UL_CLK_UART6_SERIAL>;
				clock-names = "ipg", "per";
				dmas = <&sdma 0 4 0>, <&sdma 47 4 0>;
				dma-names = "rx", "tx";
				status = "disabled";
			};*/
		};

	};
};


/ {
    model = "sonnepower spl0602";
    compatible = "fsl,imx6ul-14x14-evk", "fsl,imx6ul";

	chosen {
		stdout-path = &uart5;
	};

	memory {
		reg = <0x80000000 0x20000000>; /* 512M */
	};

    reserved-memory {
        #address-cells = <1>;
        #size-cells = <1>;
        ranges;

        linux,cma {
            compatible = "shared-dma-pool";
            reusable;
            size = <0x2000000>;		/* 32M */
            linux,cma-default;
        };
    };

	/* add by Codebreaker */
	regulators {
		compatible = "simple-bus";
		#address-cells = <1>;
		#size-cells = <0>;

		reg_3p3v: 3p3v {
			compatible = "regulator-fixed";
			regulator-name = "3P3V";
			regulator-min-microvolt = <3300000>;
			regulator-max-microvolt = <3300000>;
			regulator-always-on;
		};

		reg_1p8v: 1p8v {
			compatible = "regulator-fixed";
			regulator-name = "1P8V";
			regulator-min-microvolt = <1800000>;
			regulator-max-microvolt = <1800000>;
			regulator-always-on;
		};
	};
};

&cpu0 {
	arm-supply = <&reg_arm>;
	soc-supply = <&reg_soc>;
};

&clks {
	assigned-clocks = <&clks IMX6UL_CLK_PLL4_AUDIO_DIV>;
	assigned-clock-rates = <786432000>;
};

&fec2 {
	pinctrl-names = "default";
	pinctrl-0 = <&pinctrl_enet2>;
	phy-mode = "rmii";
	phy-handle = <&ethphy0>;
	status = "okay";
        /*phy-reset-gpios=<&gpio1 10 0>;*/

	mdio {
		#address-cells = <1>;
		#size-cells = <0>;

		ethphy0: ethernet-phy@1 {
			compatible = "ethernet-phy-ieee802.3-c22";
			reg = <1>;
		};
	};
};

&gpc {
	fsl,cpu_pupscr_sw2iso = <0x1>;
	fsl,cpu_pupscr_sw = <0x0>;
	fsl,cpu_pdnscr_iso2sw = <0x1>;
	fsl,cpu_pdnscr_iso = <0x1>;
/*	fsl,wdog-reset = <1>;*/ /* watchdog select of reset source */
	fsl,ldo-bypass = <0>; /* use ldo-bypass, u-boot will check it and configure */
};

&pwm2 {
	pinctrl-names = "default";
	pinctrl-0 = <&pinctrl_pwm2>;
	status = "okay";
};

&uart1 {
	pinctrl-names = "default";
	pinctrl-0 = <&pinctrl_uart1>;
	status = "okay";
};

&uart3 {
	pinctrl-names = "default";
	pinctrl-0 = <&pinctrl_uart3>;
	status = "okay";
};

&uart4 {
	pinctrl-names = "default";
	pinctrl-0 = <&pinctrl_uart4>;
	status = "okay";
};

&uart5 {
	pinctrl-names = "default";
	pinctrl-0 = <&pinctrl_uart5>;
	status = "okay";
};

&uart7 {
	pinctrl-names = "default";
	pinctrl-0 = <&pinctrl_uart7>;
	status = "okay";
};

&uart8 {
	pinctrl-names = "default";
	pinctrl-0 = <&pinctrl_uart8>;
	status = "okay";
};

&usbotg1 {
	pinctrl-names = "default";
	pinctrl-0 = <&pinctrl_usbotg1>;
	dr_mode = "otg";
	hnp-disable;
	srp-disable;
	adp-disable;
    disable-over-current;
	status = "okay";
};


&gpmi {
	status = "disabled";
};

&usbphy1 {
	tx-d-cal = <0x5>;
};

&usbphy2 {
	tx-d-cal = <0x5>;
};

&usdhc2 {
    pinctrl-names = "default", "state_100mhz", "state_200mhz";
    pinctrl-0 = <&pinctrl_usdhc2_8bit>;
    pinctrl-1 = <&pinctrl_usdhc2_8bit_100mhz>;
    pinctrl-2 = <&pinctrl_usdhc2_8bit_200mhz>;
    keep-power-in-suspend;
    enable-sdio-wakeup;
    wifi-host;
	status = "okay";
};

&adc1 {
	pinctrl-names = "default";
	pinctrl-0 = <&pinctrl_adc1>;
	vref-supply =<&reg_3p3v>;
	num-channels = <9>;
	status = "okay";
};

&iomuxc {
	pinctrl-names = "default";
	pinctrl-0 = <&pinctrl_hog_1>;
	imx6ul-evk {
		pinctrl_hog_1: hoggrp-1 {
			fsl,pins = <
				MX6UL_PAD_JTAG_MOD__GPIO1_IO10          0x17059  /*eth1 reset*/

				//MX6UL_PAD_JTAG_TMS__GPIO1_IO11           0x17059  /*EN_WDI*/
				//MX6UL_PAD_JTAG_TDI__GPIO1_IO13		 0x17059  /*Master_Ctr_Slave_MR*/

	            MX6UL_PAD_SNVS_TAMPER0__GPIO5_IO00	0x17059 /* AII_CONFIG 15*/
				MX6UL_PAD_SNVS_TAMPER1__GPIO5_IO01	0x17059 /* AII_CONFIG 13*/
				MX6UL_PAD_SNVS_TAMPER2__GPIO5_IO02	0x17059 /* AII_CONFIG 12*/
				MX6UL_PAD_SNVS_TAMPER3__GPIO5_IO03	0x17059 /* AII_CONFIG 14*/
				//MX6UL_PAD_SNVS_TAMPER4__GPIO5_IO04	0x17059 /* AIR_CONFIG 27*/
				MX6UL_PAD_SNVS_TAMPER5__GPIO5_IO05	0x17059 /* AII_CONFIG 11*/
				MX6UL_PAD_SNVS_TAMPER6__GPIO5_IO06	0x17059 /* AII_CONFIG 08*/
				//MX6UL_PAD_SNVS_TAMPER7__GPIO5_IO07	0x17059 /* AIR_CONFIG 26*/
				MX6UL_PAD_SNVS_TAMPER8__GPIO5_IO08	0x17059 /* AII_CONFIG 09*/
				MX6UL_PAD_SNVS_TAMPER9__GPIO5_IO09	0x17059 /* AII_CONFIG 10 */

				MX6UL_PAD_CSI_DATA07__GPIO4_IO28	0x17059 /* AII_CONFIG 36 */

				MX6UL_PAD_CSI_DATA03__GPIO4_IO24        0x17059 /* AII_CONFIG 37 */

				MX6UL_PAD_CSI_DATA02__GPIO4_IO23         0x17059 /* CS0 */
				MX6UL_PAD_CSI_DATA01__GPIO4_IO22         0x17059 /* CS1 */
				MX6UL_PAD_CSI_DATA00__GPIO4_IO21         0x17059 /* CS2 */ 

				//MX6UL_PAD_CSI_MCLK__GPIO4_IO17           0x17059 /* LMaster0 D+ */  -->BD_RXD
				//MX6UL_PAD_CSI_PIXCLK__GPIO4_IO18         0x17059 /* NLPWR0Hold0Master*/ -->BD_TXD
                //MX6UL_PAD_SD1_CLK__GPIO2_IO17          0x17059 /*FRAM_WP --> FRAM_SCK*/ 
				MX6UL_PAD_SD1_CMD__GPIO2_IO16 	        0x17059 /*FRAM_CS*/
				MX6UL_PAD_SD1_DATA1__GPIO2_IO19        0x17059 /*FRAM_mosi*/
				MX6UL_PAD_SD1_DATA2__GPIO2_IO20 	0x17059 /*FRAM_miso*/
				//MX6UL_PAD_SD1_DATA3__GPIO2_IO21 	0x17059 /*FRAM_sck -->USB_OTG2_ID */
			>;
		};

		pinctrl_wdt: wdtgrp {
			fsl,pins = <
				MX6UL_PAD_JTAG_TRST_B__GPIO1_IO15	0x17059 /* wdog */
			>;
		};

		pinctrl_enet2: enet2grp {
			fsl,pins = <
				MX6UL_PAD_ENET1_TX_EN__ENET2_MDC  	0x1b0b0
				MX6UL_PAD_ENET1_TX_DATA1__ENET2_MDIO	0x1b0b0
				MX6UL_PAD_ENET2_RX_EN__ENET2_RX_EN	0x1b0b0
				MX6UL_PAD_ENET2_RX_ER__ENET2_RX_ER	0x1b0b0
				MX6UL_PAD_ENET2_RX_DATA0__ENET2_RDATA00	0x1b0b0
				MX6UL_PAD_ENET2_RX_DATA1__ENET2_RDATA01	0x1b0b0
				MX6UL_PAD_ENET2_TX_EN__ENET2_TX_EN	0x1b0b0
				MX6UL_PAD_ENET2_TX_DATA0__ENET2_TDATA00	0x1b0b0
				MX6UL_PAD_ENET2_TX_DATA1__ENET2_TDATA01	0x1b0b0
				MX6UL_PAD_ENET2_TX_CLK__ENET2_REF_CLK2	0x4001b031
			>;
		};

		pinctrl_flexcan1: flexcan1grp{
			fsl,pins = <
				MX6UL_PAD_ENET1_RX_DATA1__FLEXCAN1_RX 	0x1b020
				MX6UL_PAD_ENET1_RX_DATA0__FLEXCAN1_TX	0x1b020
			>;
		};

		pinctrl_flexcan2: flexcan2grp{
			fsl,pins = <
				MX6UL_PAD_ENET1_TX_DATA0__FLEXCAN2_RX 	0x1b020
				MX6UL_PAD_ENET1_RX_EN__FLEXCAN2_TX	0x1b020
			>;
		};

		pinctrl_pwm2: pwm2grp {
			fsl,pins = <
				MX6UL_PAD_GPIO1_IO09__PWM2_OUT 	0x110b0
			>;
		};

		pinctrl_uart3: uart3grp {
			fsl,pins = <
				MX6UL_PAD_UART3_TX_DATA__UART3_DCE_TX	0x1b0b1
				MX6UL_PAD_UART3_RX_DATA__UART3_DCE_RX	0x1b0b1
			>;
		};

                /*BT**/
		pinctrl_uart1: uart1grp {
			fsl,pins = <
				MX6UL_PAD_UART1_TX_DATA__UART1_DCE_TX 0x1b0b1
				MX6UL_PAD_UART1_RX_DATA__UART1_DCE_RX 0x1b0b1
			>;
		};

		pinctrl_uart4: uart4grp {
			fsl,pins = <
				MX6UL_PAD_UART4_TX_DATA__UART4_DCE_TX	0x1b0b1
				MX6UL_PAD_UART4_RX_DATA__UART4_DCE_RX	0x1b0b1
			>;
		};

		pinctrl_uart5: uart5grp {
			fsl,pins = <
				MX6UL_PAD_UART5_TX_DATA__UART5_DCE_TX	0x1b0b1
				MX6UL_PAD_UART5_RX_DATA__UART5_DCE_RX	0x1b0b1
			>;
		};

		pinctrl_uart7: uart7grp {
			fsl,pins = <
				MX6UL_PAD_LCD_DATA16__UART7_DCE_TX	0x1b0b1
				MX6UL_PAD_LCD_DATA17__UART7_DCE_RX	0x1b0b1
			>;
		};

		pinctrl_uart8: uart8grp {
			fsl,pins = <
				MX6UL_PAD_LCD_DATA20__UART8_DCE_TX	0x1b0b1
				MX6UL_PAD_LCD_DATA21__UART8_DCE_RX	0x1b0b1
			>;
		};

		pinctrl_usbotg1: usbotg1grp {
			fsl,pins = <
				MX6UL_PAD_SD1_DATA0__ANATOP_OTG1_ID  0x17059
			>;
		};

       pinctrl_usdhc2: usdhc2grp {
            fsl,pins = <
				MX6UL_PAD_NAND_RE_B__USDHC2_CLK     0x10069
				MX6UL_PAD_NAND_WE_B__USDHC2_CMD     0x17059
				MX6UL_PAD_NAND_DATA00__USDHC2_DATA0 0x17059
				MX6UL_PAD_NAND_DATA01__USDHC2_DATA1 0x17059
				MX6UL_PAD_NAND_DATA02__USDHC2_DATA2 0x17059
				MX6UL_PAD_NAND_DATA03__USDHC2_DATA3 0x17059
            >;
        };

        pinctrl_usdhc2_100mhz: usdhc2grp100mhz {
            fsl,pins = <
				MX6UL_PAD_NAND_RE_B__USDHC2_CLK     0x10069
				MX6UL_PAD_NAND_WE_B__USDHC2_CMD     0x17059
				MX6UL_PAD_NAND_DATA00__USDHC2_DATA0 0x17059
				MX6UL_PAD_NAND_DATA01__USDHC2_DATA1 0x17059
				MX6UL_PAD_NAND_DATA02__USDHC2_DATA2 0x17059
				MX6UL_PAD_NAND_DATA03__USDHC2_DATA3 0x17059
            >;
        };

        pinctrl_usdhc2_200mhz: usdhc2grp200mhz {
            fsl,pins = <
				MX6UL_PAD_NAND_RE_B__USDHC2_CLK     0x10069
				MX6UL_PAD_NAND_WE_B__USDHC2_CMD     0x17059
				MX6UL_PAD_NAND_DATA00__USDHC2_DATA0 0x17059
				MX6UL_PAD_NAND_DATA01__USDHC2_DATA1 0x17059
				MX6UL_PAD_NAND_DATA02__USDHC2_DATA2 0x17059
				MX6UL_PAD_NAND_DATA03__USDHC2_DATA3 0x17059
            >;
        };
		pinctrl_usdhc2_8bit: usdhc2grp_8bit {
			fsl,pins = <
				MX6UL_PAD_NAND_RE_B__USDHC2_CLK     0x10069
				MX6UL_PAD_NAND_WE_B__USDHC2_CMD     0x17059
				MX6UL_PAD_NAND_DATA00__USDHC2_DATA0 0x17059
				MX6UL_PAD_NAND_DATA01__USDHC2_DATA1 0x17059
				MX6UL_PAD_NAND_DATA02__USDHC2_DATA2 0x17059
				MX6UL_PAD_NAND_DATA03__USDHC2_DATA3 0x17059
				MX6UL_PAD_NAND_DATA04__USDHC2_DATA4 0x17059
				MX6UL_PAD_NAND_DATA05__USDHC2_DATA5 0x17059
				MX6UL_PAD_NAND_DATA06__USDHC2_DATA6 0x17059
				MX6UL_PAD_NAND_DATA07__USDHC2_DATA7 0x17059
			>;
		};

		pinctrl_usdhc2_8bit_100mhz: usdhc2grp_8bit_100mhz {
			fsl,pins = <
				MX6UL_PAD_NAND_RE_B__USDHC2_CLK     0x100b9
				MX6UL_PAD_NAND_WE_B__USDHC2_CMD     0x170b9
				MX6UL_PAD_NAND_DATA00__USDHC2_DATA0 0x170b9
				MX6UL_PAD_NAND_DATA01__USDHC2_DATA1 0x170b9
				MX6UL_PAD_NAND_DATA02__USDHC2_DATA2 0x170b9
				MX6UL_PAD_NAND_DATA03__USDHC2_DATA3 0x170b9
				MX6UL_PAD_NAND_DATA04__USDHC2_DATA4 0x170b9
				MX6UL_PAD_NAND_DATA05__USDHC2_DATA5 0x170b9
				MX6UL_PAD_NAND_DATA06__USDHC2_DATA6 0x170b9
				MX6UL_PAD_NAND_DATA07__USDHC2_DATA7 0x170b9
			>;
		};

		pinctrl_usdhc2_8bit_200mhz: usdhc2grp_8bit_200mhz {
			fsl,pins = <
				MX6UL_PAD_NAND_RE_B__USDHC2_CLK     0x100f9
				MX6UL_PAD_NAND_WE_B__USDHC2_CMD     0x170f9
				MX6UL_PAD_NAND_DATA00__USDHC2_DATA0 0x170f9
				MX6UL_PAD_NAND_DATA01__USDHC2_DATA1 0x170f9
				MX6UL_PAD_NAND_DATA02__USDHC2_DATA2 0x170f9
				MX6UL_PAD_NAND_DATA03__USDHC2_DATA3 0x170f9
				MX6UL_PAD_NAND_DATA04__USDHC2_DATA4 0x170f9
				MX6UL_PAD_NAND_DATA05__USDHC2_DATA5 0x170f9
				MX6UL_PAD_NAND_DATA06__USDHC2_DATA6 0x170f9
				MX6UL_PAD_NAND_DATA07__USDHC2_DATA7 0x170f9
			>;
		};

		pinctrl_adc1: adc1grp {
			fsl,pins = <
				MX6UL_PAD_GPIO1_IO00__GPIO1_IO00	0xb0
				MX6UL_PAD_GPIO1_IO01__GPIO1_IO01	0xb0
				MX6UL_PAD_GPIO1_IO02__GPIO1_IO02	0xb0
				MX6UL_PAD_GPIO1_IO03__GPIO1_IO03	0xb0
				MX6UL_PAD_GPIO1_IO04__GPIO1_IO04	0xb0
				MX6UL_PAD_GPIO1_IO05__GPIO1_IO05	0xb0
				MX6UL_PAD_GPIO1_IO06__GPIO1_IO06	0xb0
				MX6UL_PAD_GPIO1_IO07__GPIO1_IO07	0xb0
				MX6UL_PAD_GPIO1_IO08__GPIO1_IO08	0xb0		
				//MX6UL_PAD_GPIO1_IO09__GPIO1_IO09	0xb0	
			>;
		};

		pinctrl_ecspi3_cs_1: ecspi3_cs_grp-1 {
			fsl,pins = <
				MX6UL_PAD_UART2_TX_DATA__GPIO1_IO20	0x80000000
			>;
		};

		pinctrl_ecspi3_1: escpi3grp {
			fsl,pins = <
				MX6UL_PAD_UART2_RX_DATA__ECSPI3_SCLK 	0x100b1
				MX6UL_PAD_UART2_CTS_B__ECSPI3_MOSI	0x100b1
				MX6UL_PAD_UART2_RTS_B__ECSPI3_MISO	0x100b1
			>;
		};

		pinctrl_i2c: i2cgrp {
			fsl,pins = <
				MX6UL_PAD_CSI_HSYNC__I2C2_SCL	        0x4001b8b0  /*scl */
				MX6UL_PAD_CSI_VSYNC__I2C2_SDA  	0x4001b8b0  /*sda */
			>;
		};
	};
};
